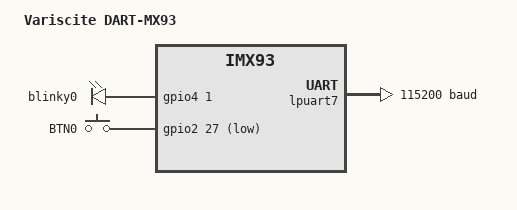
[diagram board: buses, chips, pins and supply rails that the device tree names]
/*
 * Copyright 2025 Variscite Ltd.
 * Copyright 2024 NXP
 *
 * SPDX-License-Identifier: Apache-2.0
 */

/dts-v1/;

#include <nxp/nxp_imx93_m33.dtsi>
#include "imx93_var_dart-pinctrl.dtsi"
#include "imx93_var_dart-m33-common.dtsi"
#include <zephyr/dt-bindings/gpio/gpio.h>
#include <zephyr/dt-bindings/input/input-event-codes.h>

/ {
	model = "Variscite DART-MX93";
	compatible = "nxp,imx93_var_dart";

	chosen {
		/* TCM */
		zephyr,flash = &itcm;
		zephyr,sram = &dtcm;

		zephyr,console = &lpuart7;
		zephyr,shell-uart = &lpuart7;
	};

	aliases {
		led0 = &blinky0;
		sw0 = &button0;
	};

	leds {
		compatible = "gpio-leds";

		blinky0: blinky_0 {
			gpios = <&gpio4 1 GPIO_ACTIVE_HIGH>;
		};
	};

	keys {
		compatible = "gpio-keys";

		button0: btn_0 {
			label = "BTN0";
			gpios = <&gpio2 27 (GPIO_PULL_UP | GPIO_ACTIVE_LOW)>;
			zephyr,code = <INPUT_KEY_0>;
		};
	};
};

&lpuart7 {
	status = "okay";
	current-speed = <115200>;
	pinctrl-0 = <&uart7_default>;
	pinctrl-names = "default";
};

&gpio2 {
	status = "okay";
};

&gpio4 {
	status = "okay";
};
